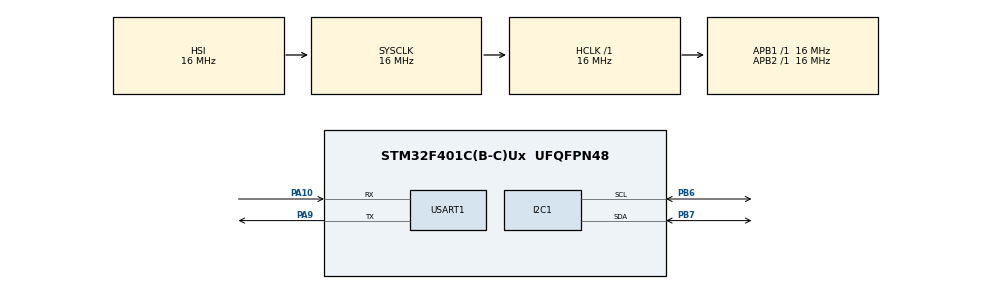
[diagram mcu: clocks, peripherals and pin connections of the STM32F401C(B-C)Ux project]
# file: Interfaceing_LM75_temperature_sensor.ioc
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I2C1.I2C_Mode=I2C_Fast
Mcu.Family=STM32F4
Mcu.Name=STM32F401C(B-C)Ux
Mcu.Package=UFQFPN48
NVIC.PriorityGroup=NVIC_PRIORITYGROUP_4
PA10.Mode=Asynchronous
PA10.Signal=USART1_RX
PA9.Mode=Asynchronous
PA9.Signal=USART1_TX
PB6.Mode=I2C
PB6.Signal=I2C1_SCL
PB7.Mode=I2C
PB7.Signal=I2C1_SDA
ProjectManager.HeapSize=0x200
ProjectManager.StackSize=0x400
ProjectManager.TargetToolchain=STM32CubeIDE
RCC.AHBFreq_Value=16000000
RCC.APB1Freq_Value=16000000
RCC.APB2Freq_Value=16000000
RCC.CortexFreq_Value=16000000
RCC.HSE_VALUE=25000000
RCC.HSI_VALUE=16000000
RCC.LSE_VALUE=32768
RCC.SYSCLKFreq_VALUE=16000000
RCC.VCOOutputFreq_Value=192000000
USART1.VirtualMode=VM_ASYNC
board=custom

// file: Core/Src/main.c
/* USER CODE BEGIN Header */
/**
  ******************************************************************************
  * @file           : main.c
  * @brief          : Main program body
  ******************************************************************************
  * @attention
  *
  * Copyright (c) 2025 STMicroelectronics.
  * All rights reserved.
  *
  * This software is licensed under terms that can be found in the LICENSE file
  * in the root directory of this software component.
  * If no LICENSE file comes with this software, it is provided AS-IS.
  *
  ******************************************************************************
  */
/* USER CODE END Header */
#include "main.h"
#include "string.h"

/* USER CODE BEGIN Includes */
// LM75 I2C address (check your sensor datasheet; the default is usually 0x48)
#define LM75_ADDR 0x90  // Address is 0x48 shifted left by 1 (I2C address: 0x48 << 1)

// LM75 Register addresses
#define LM75_TEMP_REG 0x00  // Temperature register
/* USER CODE END Includes */

I2C_HandleTypeDef hi2c1;

UART_HandleTypeDef huart1;

void SystemClock_Config(void);
static void MX_GPIO_Init(void);
static void MX_I2C1_Init(void);
static void MX_USART1_UART_Init(void);
uint8_t LM75_ReadTemperature(void);
void UART_Transmit(char* str);

int main(void)
{
	// Initialize the MCU peripherals
	  HAL_Init();
	  SystemClock_Config();
	  MX_GPIO_Init();
	  MX_I2C1_Init();
	  MX_USART1_UART_Init();

	  // Buffer to hold the temperature reading
	  uint8_t temp_raw;
	  float temperature;
	  char temp_str[50];

	  while (1) {
	    // Read the temperature from the LM75
	    temp_raw = LM75_ReadTemperature();

	    // Convert raw temperature to Celsius (LM75 returns temperature in 1/2 degree Celsius)
	    temperature = (float)temp_raw / 2.0;

	    // Format the temperature into a string
	    snprintf(temp_str, sizeof(temp_str), "Temperature: %.2f C\r\n", temperature);

	    // Send the temperature over UART
	    UART_Transmit(temp_str);

	    // Delay before the next reading
	    HAL_Delay(1000);  // 1-second delay
	  }
}

void SystemClock_Config(void)
{
  RCC_OscInitTypeDef RCC_OscInitStruct = {0};
  RCC_ClkInitTypeDef RCC_ClkInitStruct = {0};

  /** Configure the main internal regulator output voltage
  */
  __HAL_RCC_PWR_CLK_ENABLE();
  __HAL_PWR_VOLTAGESCALING_CONFIG(PWR_REGULATOR_VOLTAGE_SCALE2);

  /** Initializes the RCC Oscillators according to the specified parameters
  * in the RCC_OscInitTypeDef structure.
  */
  RCC_OscInitStruct.OscillatorType = RCC_OSCILLATORTYPE_HSI;
  RCC_OscInitStruct.HSIState = RCC_HSI_ON;
  RCC_OscInitStruct.HSICalibrationValue = RCC_HSICALIBRATION_DEFAULT;
  RCC_OscInitStruct.PLL.PLLState = RCC_PLL_NONE;
  if (HAL_RCC_OscConfig(&RCC_OscInitStruct) != HAL_OK)
  {
    Error_Handler();
  }

  /** Initializes the CPU, AHB and APB buses clocks
  */
  RCC_ClkInitStruct.ClockType = RCC_CLOCKTYPE_HCLK|RCC_CLOCKTYPE_SYSCLK
                              |RCC_CLOCKTYPE_PCLK1|RCC_CLOCKTYPE_PCLK2;
  RCC_ClkInitStruct.SYSCLKSource = RCC_SYSCLKSOURCE_HSI;
  RCC_ClkInitStruct.AHBCLKDivider = RCC_SYSCLK_DIV1;
  RCC_ClkInitStruct.APB1CLKDivider = RCC_HCLK_DIV1;
  RCC_ClkInitStruct.APB2CLKDivider = RCC_HCLK_DIV1;

  if (HAL_RCC_ClockConfig(&RCC_ClkInitStruct, FLASH_LATENCY_0) != HAL_OK)
  {
    Error_Handler();
  }
}

static void MX_I2C1_Init(void)
{

  hi2c1.Instance = I2C1;
  hi2c1.Init.ClockSpeed = 400000;
  hi2c1.Init.DutyCycle = I2C_DUTYCYCLE_2;
  hi2c1.Init.OwnAddress1 = 0;
  hi2c1.Init.AddressingMode = I2C_ADDRESSINGMODE_7BIT;
  hi2c1.Init.DualAddressMode = I2C_DUALADDRESS_DISABLE;
  hi2c1.Init.OwnAddress2 = 0;
  hi2c1.Init.GeneralCallMode = I2C_GENERALCALL_DISABLE;
  hi2c1.Init.NoStretchMode = I2C_NOSTRETCH_DISABLE;
  if (HAL_I2C_Init(&hi2c1) != HAL_OK)
  {
    Error_Handler();
  }

}

// Function to read temperature data from LM75
uint8_t LM75_ReadTemperature(void) {
  uint8_t temp_data[2];

  // Read 2 bytes from the LM75's temperature register
  if (HAL_I2C_Mem_Read(&hi2c1, LM75_ADDR, LM75_TEMP_REG, I2C_MEMADD_SIZE_8BIT, temp_data, 2, 1000) != HAL_OK) {
    // Error reading from the sensor
    return 0;
  }

  // Combine the two bytes to get the temperature value
  uint8_t temp = temp_data[0];  // The first byte contains the temperature
  return temp;
}

// Function to send data over UART
void UART_Transmit(char* str) {
  if (HAL_UART_Transmit(&huart1, (uint8_t*)str, strlen(str), 1000) != HAL_OK) {
    Error_Handler();
  }
}
static void MX_USART1_UART_Init(void)
{

  huart1.Instance = USART1;
  huart1.Init.BaudRate = 115200;
  huart1.Init.WordLength = UART_WORDLENGTH_8B;
  huart1.Init.StopBits = UART_STOPBITS_1;
  huart1.Init.Parity = UART_PARITY_NONE;
  huart1.Init.Mode = UART_MODE_TX_RX;
  huart1.Init.HwFlowCtl = UART_HWCONTROL_NONE;
  huart1.Init.OverSampling = UART_OVERSAMPLING_16;
  if (HAL_UART_Init(&huart1) != HAL_OK)
  {
    Error_Handler();
  }

}

static void MX_GPIO_Init(void)
{

  /* GPIO Ports Clock Enable */
  __HAL_RCC_GPIOA_CLK_ENABLE();
  __HAL_RCC_GPIOB_CLK_ENABLE();

}

void Error_Handler(void)
{
  __disable_irq();
  while (1)
  {
  }
}
